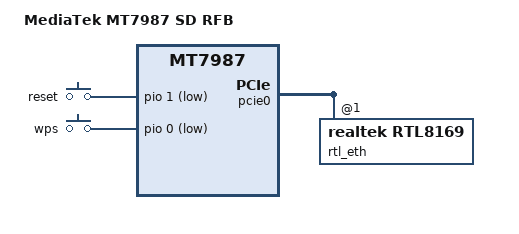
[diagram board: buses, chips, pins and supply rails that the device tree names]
// SPDX-License-Identifier: (GPL-2.0 OR MIT)

/dts-v1/;
#include "mt7987a.dtsi"
#include "mt7987-sd.dtsi"
#include <dt-bindings/input/input.h>

/ {
	model = "MediaTek MT7987 SD RFB";
	compatible = "mediatek,mt7987a-sd",
		     "mediatek,mt7987a", "mediatek,mt7987";

	chosen {
		bootargs = "console=ttyS0,115200n1 loglevel=8  \
			    earlycon=uart8250,mmio32,0x11000000 \
			    pci=pcie_bus_perf ubi.block=0,firmware \
			    root=/dev/fit0 rootwait";
	};

	gpio-keys {
		compatible = "gpio-keys";

		reset {
			label = "reset";
			linux,code = <KEY_RESTART>;
			gpios = <&pio 1 GPIO_ACTIVE_LOW>;
			debounce-interval = <10>;
		};

		wps {
			label = "wps";
			linux,code = <KEY_WPS_BUTTON>;
			gpios = <&pio 0 GPIO_ACTIVE_LOW>;
			debounce-interval = <10>;
		};
	};
};

&pcie0 {
	status = "okay";

	/* PCI device node for an on-board Realtek RTL8169/8125 family NIC.
	 * Declaring device_type = "pci" and a reg entry makes the device
	 * visible to U-Boot's OF/PCI infrastructure so the built-in
	 * rtl8169 driver can bind after PCI enumeration. The reg cell
	 * here is a simple representation for bus 2, device 0, function 0.
	 * Adjust if your board enumerates the device at a different address.
	 */
	/* PCI device is enumerated on bus 1 (seen as 01:00.0). Use bus/device/function
	 * encoding so U-Boot maps BARs correctly and the rtl driver can access MMIO.
	 */
	rtl_eth: ethernet@1,0 {
		compatible = "realtek,rtl8169";
		device_type = "pci";
		/* PCI address: bus 1, device 0, function 0 */
		reg = <0x01 0x00 0x00>;
		status = "okay";
	};
};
